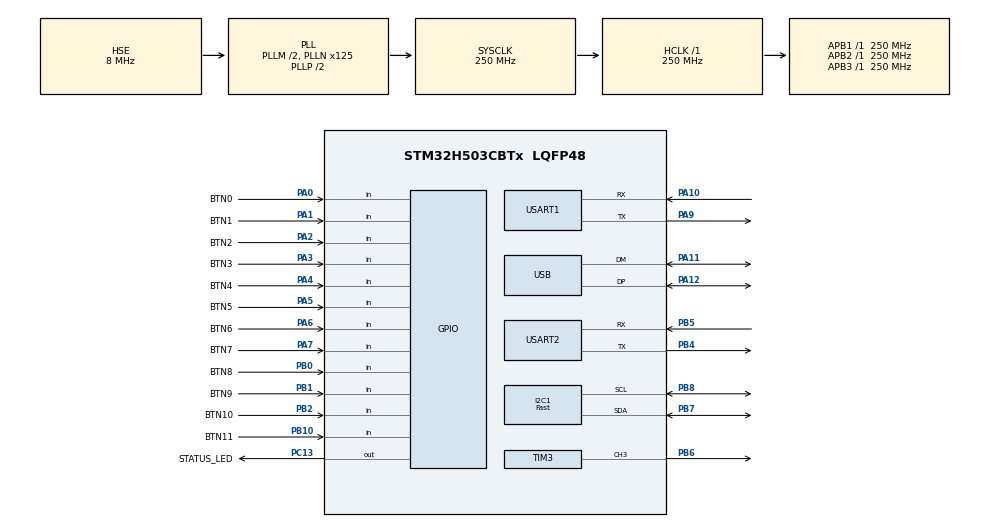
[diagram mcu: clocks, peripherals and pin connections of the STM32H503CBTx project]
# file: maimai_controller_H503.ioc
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BOOTPATH.BootPathName=LEGACY
BOOTPATH.UserSelectedBootPath=LEGACY
GPDMA1.DESTDATAWIDTH_GPDMACH0=DMA_DEST_DATAWIDTH_HALFWORD
GPDMA1.DIRECTION_GPDMACH0=DMA_MEMORY_TO_PERIPH
GPDMA1.IPHANDLE_GPDMACH0-SIMPLEREQUEST_GPDMACH0=__NULL
GPDMA1.PRIORITY_GPDMACH0=DMA_LOW_PRIORITY_HIGH_WEIGHT
GPDMA1.REQUEST_GPDMACH0=GPDMA1_REQUEST_TIM3_CH3
GPDMA1.SRCINC_GPDMACH0=DMA_SINC_INCREMENTED
I2C1.I2C_Speed_Mode=I2C_Fast
I2C1.Speed=400
I2C1.Timing=0x10C043E5
Mcu.Family=STM32H5
Mcu.Name=STM32H503CBTx
Mcu.Package=LQFP48
NVIC.GPDMA1_Channel0_IRQn=true\:0\:0\:false\:false\:true\:false\:true\:true
NVIC.I2C1_ER_IRQn=true\:0\:0\:false\:false\:true\:true\:true\:true
NVIC.I2C1_EV_IRQn=true\:0\:0\:false\:false\:true\:true\:true\:true
NVIC.PriorityGroup=NVIC_PRIORITYGROUP_4
NVIC.USART2_IRQn=true\:0\:0\:false\:false\:true\:true\:true\:true
NVIC.USB_DRD_FS_IRQn=true\:0\:0\:false\:false\:true\:true\:true\:true
PA0.GPIO_Label=BTN0
PA0.GPIO_Mode=GPIO_MODE_INPUT
PA0.GPIO_PuPd=GPIO_PULLUP
PA0.Signal=GPIO_Input
PA1.GPIO_Label=BTN1
PA1.GPIO_Mode=GPIO_MODE_INPUT
PA1.GPIO_PuPd=GPIO_PULLUP
PA1.Signal=GPIO_Input
PA10.Mode=Asynchronous
PA10.Signal=USART1_RX
PA11.Mode=Device
PA11.Signal=USB_DM
PA12.Mode=Device
PA12.Signal=USB_DP
PA13(JTMS/SWDIO).Mode=Serial_Wire
PA13(JTMS/SWDIO).Signal=DEBUG_JTMS-SWDIO
PA14(JTCK/SWCLK).Mode=Serial_Wire
PA14(JTCK/SWCLK).Signal=DEBUG_JTCK-SWCLK
PA2.GPIO_Label=BTN2
PA2.GPIO_Mode=GPIO_MODE_INPUT
PA2.GPIO_PuPd=GPIO_PULLUP
PA2.Signal=GPIO_Input
PA3.GPIO_Label=BTN3
PA3.GPIO_Mode=GPIO_MODE_INPUT
PA3.GPIO_PuPd=GPIO_PULLUP
PA3.Signal=GPIO_Input
PA4.GPIO_Label=BTN4
PA4.GPIO_Mode=GPIO_MODE_INPUT
PA4.GPIO_PuPd=GPIO_PULLUP
PA4.Signal=GPIO_Input
PA5.GPIO_Label=BTN5
PA5.GPIO_Mode=GPIO_MODE_INPUT
PA5.GPIO_PuPd=GPIO_PULLUP
PA5.Signal=GPIO_Input
PA6.GPIO_Label=BTN6
PA6.GPIO_Mode=GPIO_MODE_INPUT
PA6.GPIO_PuPd=GPIO_PULLUP
PA6.Signal=GPIO_Input
PA7.GPIO_Label=BTN7
PA7.GPIO_Mode=GPIO_MODE_INPUT
PA7.GPIO_PuPd=GPIO_PULLUP
PA7.Signal=GPIO_Input
PA9.Mode=Asynchronous
PA9.Signal=USART1_TX
PB0.GPIO_Label=BTN8
PB0.GPIO_Mode=GPIO_MODE_INPUT
PB0.GPIO_PuPd=GPIO_PULLUP
PB0.Signal=GPIO_Input
PB1.GPIO_Label=BTN9
PB1.GPIO_Mode=GPIO_MODE_INPUT
PB1.GPIO_PuPd=GPIO_PULLUP
PB1.Signal=GPIO_Input
PB10.GPIO_Label=BTN11
PB10.GPIO_Mode=GPIO_MODE_INPUT
PB10.GPIO_PuPd=GPIO_PULLUP
PB10.Signal=GPIO_Input
PB2.GPIO_Label=BTN10
PB2.GPIO_PuPd=GPIO_PULLUP
PB2.Signal=GPIO_Input
PB4(NJTRST).Mode=Asynchronous
PB4(NJTRST).Signal=USART2_TX
PB5.Mode=Asynchronous
PB5.Signal=USART2_RX
PB6.Signal=S_TIM3_CH3
PB7.Mode=I2C
PB7.Signal=I2C1_SDA
PB8.Mode=I2C
PB8.Signal=I2C1_SCL
PC13.GPIO_Label=STATUS_LED
PC13.PinState=GPIO_PIN_SET
PC13.Signal=GPIO_Output
PH0-OSC_IN(PH0).Mode=HSE-External-Oscillator
PH0-OSC_IN(PH0).Signal=RCC_OSC_IN
PH1-OSC_OUT(PH1).Mode=HSE-External-Oscillator
PH1-OSC_OUT(PH1).Signal=RCC_OSC_OUT
ProjectManager.HeapSize=0x200
ProjectManager.StackSize=0x400
ProjectManager.TargetToolchain=STM32CubeIDE
RCC.ADCFreq_Value=250000000
RCC.AHBCLKDivider=RCC_SYSCLK_DIV1
RCC.AHBFreq_Value=250000000
RCC.APB1CLKDivider=RCC_HCLK_DIV1
RCC.APB1Freq_Value=250000000
RCC.APB1TimFreq_Value=250000000
RCC.APB2CLKDivider=RCC_HCLK_DIV1
RCC.APB2Freq_Value=250000000
RCC.APB2TimFreq_Value=250000000
RCC.APB3CLKDivider=RCC_HCLK_DIV1
RCC.APB3Freq_Value=250000000
RCC.CSI_VALUE=4000000
RCC.CortexFreq_Value=250000000
RCC.EPOD_VALUE=8000000
RCC.EnbaleCSS=true
RCC.HCLKFreq_Value=250000000
RCC.HSE_VALUE=8000000
RCC.HSI48_VALUE=48000000
RCC.HSI_VALUE=64000000
RCC.I2C1CLockSelection=RCC_I2C1CLKSOURCE_PCLK1
RCC.LSE_VALUE=32768
RCC.LSIRC_VALUE=32000
RCC.PLL1P=2
RCC.PLL1Q=2
RCC.PLL1R=2
RCC.PLL2FRACN=0
RCC.PLL2M=2
RCC.PLL2Source=RCC_PLL2_SOURCE_HSE
RCC.PLLFRACN=0
RCC.PLLM=2
RCC.PLLN=125
RCC.PLLSourceVirtual=RCC_PLL1_SOURCE_HSE
RCC.SYSCLKFreq_VALUE=250000000
RCC.SYSCLKSource=RCC_SYSCLKSOURCE_PLLCLK
RCC.USBCLockSelection=RCC_USBCLKSOURCE_HSI48
RCC.USBFreq_Value=48000000
RCC.VCOOutputFreq_Value=500000000
SH.S_TIM3_CH3.0=TIM3_CH3,PWM Generation3 CH3
TIM3.Channel-PWM\ Generation3\ CH3=TIM_CHANNEL_3
USART1.VirtualMode-Asynchronous=VM_ASYNC
USART2.VirtualMode-Asynchronous=VM_ASYNC
USB.VirtualMode=Device_Only
VP_BOOTPATH_VS_BOOTPATH.Mode=BP_Activate
VP_CORTEX_M33_NS_VS_Hclk.Mode=Hclk_Mode
VP_GPDMA1_VS_GPDMACH0.Mode=SIMPLEREQUEST_GPDMACH0
VP_MEMORYMAP_VS_MEMORYMAP.Mode=CurAppReg
VP_PWR_VS_LPOM.Mode=PowerOptimisation
VP_PWR_VS_SECSignals.Mode=Security/Privilege
VP_RCC_USB.Mode=CRS SYNC Source USB
VP_TIM3_VS_ClockSourceINT.Mode=Internal
board=custom

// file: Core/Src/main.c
/* USER CODE BEGIN Header */
/**
  ******************************************************************************
  * @file           : main.c
  * @brief          : Main program body
  ******************************************************************************
  * @attention
  *
  * Copyright (c) 2026 STMicroelectronics.
  * All rights reserved.
  *
  * This software is licensed under terms that can be found in the LICENSE file
  * in the root directory of this software component.
  * If no LICENSE file comes with this software, it is provided AS-IS.
  *
  ******************************************************************************
  */
/* USER CODE END Header */
#include "main.h"
#include "gpdma.h"
#include "i2c.h"
#include "tim.h"
#include "usart.h"
#include "usb.h"
#include "gpio.h"

/* USER CODE BEGIN Includes */
#include "app.h"
#include "status/status_led_app.h"
/* USER CODE END Includes */

void SystemClock_Config(void);

int main(void)
{

  /* MCU Configuration--------------------------------------------------------*/

  /* Reset of all peripherals, Initializes the Flash interface and the Systick. */
  HAL_Init();

  /* USER CODE BEGIN Init */
  status_led_app_init();

  /* USER CODE END Init */

  /* Configure the system clock */
  SystemClock_Config();

  /* Initialize all configured peripherals */
  MX_GPIO_Init();
  MX_GPDMA1_Init();
  MX_USB_PCD_Init();
  MX_I2C1_Init();
  MX_TIM3_Init();
  MX_USART1_UART_Init();
  MX_USART2_UART_Init();
  /* USER CODE BEGIN 2 */
  app_init();

  /* USER CODE END 2 */

  /* Infinite loop */
  /* USER CODE BEGIN WHILE */
	while (1)
	{
    app_task();
    /* USER CODE END WHILE */

	}
}

void SystemClock_Config(void)
{
  RCC_OscInitTypeDef RCC_OscInitStruct = {0};
  RCC_ClkInitTypeDef RCC_ClkInitStruct = {0};
  RCC_CRSInitTypeDef RCC_CRSInitStruct = {0};

  /** Configure the main internal regulator output voltage
  */
  __HAL_PWR_VOLTAGESCALING_CONFIG(PWR_REGULATOR_VOLTAGE_SCALE0);

  while(!__HAL_PWR_GET_FLAG(PWR_FLAG_VOSRDY)) {}

  /** Initializes the RCC Oscillators according to the specified parameters
  * in the RCC_OscInitTypeDef structure.
  */
  RCC_OscInitStruct.OscillatorType = RCC_OSCILLATORTYPE_HSI48|RCC_OSCILLATORTYPE_HSE;
  RCC_OscInitStruct.HSEState = RCC_HSE_ON;
  RCC_OscInitStruct.HSI48State = RCC_HSI48_ON;
  RCC_OscInitStruct.PLL.PLLState = RCC_PLL_ON;
  RCC_OscInitStruct.PLL.PLLSource = RCC_PLL1_SOURCE_HSE;
  RCC_OscInitStruct.PLL.PLLM = 2;
  RCC_OscInitStruct.PLL.PLLN = 125;
  RCC_OscInitStruct.PLL.PLLP = 2;
  RCC_OscInitStruct.PLL.PLLQ = 2;
  RCC_OscInitStruct.PLL.PLLR = 2;
  RCC_OscInitStruct.PLL.PLLRGE = RCC_PLL1_VCIRANGE_2;
  RCC_OscInitStruct.PLL.PLLVCOSEL = RCC_PLL1_VCORANGE_WIDE;
  RCC_OscInitStruct.PLL.PLLFRACN = 0;
  if (HAL_RCC_OscConfig(&RCC_OscInitStruct) != HAL_OK)
  {
    Error_Handler();
  }

  /** Initializes the CPU, AHB and APB buses clocks
  */
  RCC_ClkInitStruct.ClockType = RCC_CLOCKTYPE_HCLK|RCC_CLOCKTYPE_SYSCLK
                              |RCC_CLOCKTYPE_PCLK1|RCC_CLOCKTYPE_PCLK2
                              |RCC_CLOCKTYPE_PCLK3;
  RCC_ClkInitStruct.SYSCLKSource = RCC_SYSCLKSOURCE_PLLCLK;
  RCC_ClkInitStruct.AHBCLKDivider = RCC_SYSCLK_DIV1;
  RCC_ClkInitStruct.APB1CLKDivider = RCC_HCLK_DIV1;
  RCC_ClkInitStruct.APB2CLKDivider = RCC_HCLK_DIV1;
  RCC_ClkInitStruct.APB3CLKDivider = RCC_HCLK_DIV1;

  if (HAL_RCC_ClockConfig(&RCC_ClkInitStruct, FLASH_LATENCY_5) != HAL_OK)
  {
    Error_Handler();
  }

  /** Enable the CRS APB clock
  */
  __HAL_RCC_CRS_CLK_ENABLE();

  /** Configures CRS
  */
  RCC_CRSInitStruct.Prescaler = RCC_CRS_SYNC_DIV1;
  RCC_CRSInitStruct.Source = RCC_CRS_SYNC_SOURCE_USB;
  RCC_CRSInitStruct.Polarity = RCC_CRS_SYNC_POLARITY_RISING;
  RCC_CRSInitStruct.ReloadValue = __HAL_RCC_CRS_RELOADVALUE_CALCULATE(48000000,1000);
  RCC_CRSInitStruct.ErrorLimitValue = 34;
  RCC_CRSInitStruct.HSI48CalibrationValue = 32;

  HAL_RCCEx_CRSConfig(&RCC_CRSInitStruct);

  /** Enables the Clock Security System
  */
  HAL_RCC_EnableCSS();

  /** Configure the programming delay
  */
  __HAL_FLASH_SET_PROGRAM_DELAY(FLASH_PROGRAMMING_DELAY_2);
}

void Error_Handler(void)
{
  /* USER CODE BEGIN Error_Handler_Debug */
  /* User can add his own implementation to report the HAL error return state */
  status_led_app_set_error();
  __disable_irq();
  while (1)
  {
  }
  /* USER CODE END Error_Handler_Debug */
}
